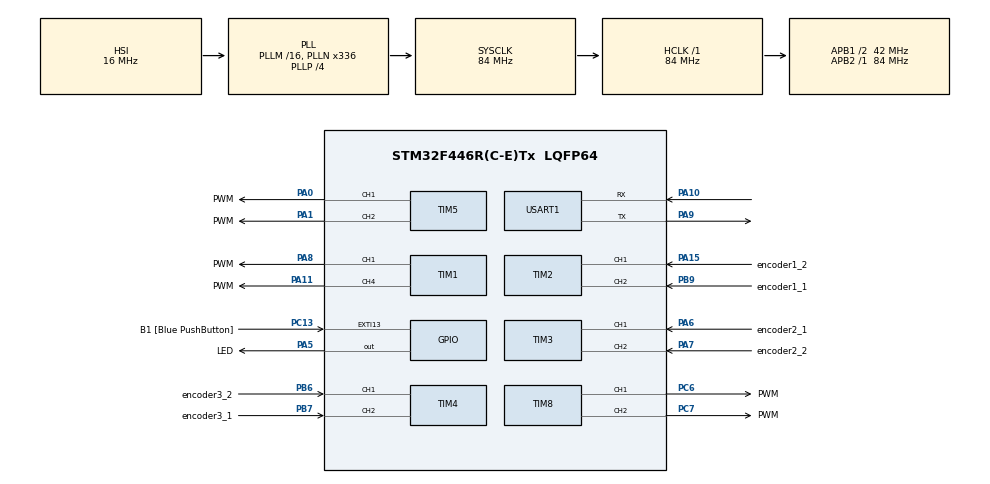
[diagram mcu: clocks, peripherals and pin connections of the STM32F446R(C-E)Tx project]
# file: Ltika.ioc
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Mcu.Family=STM32F4
Mcu.Name=STM32F446R(C-E)Tx
Mcu.Package=LQFP64
NVIC.PriorityGroup=NVIC_PRIORITYGROUP_0
PA0-WKUP.GPIO_Label=PWM
PA0-WKUP.Signal=S_TIM5_CH1
PA1.GPIO_Label=PWM
PA1.Signal=S_TIM5_CH2
PA10.Mode=Asynchronous
PA10.Signal=USART1_RX
PA11.GPIO_Label=PWM
PA11.Signal=S_TIM1_CH4
PA13.GPIO_Label=TMS
PA13.Signal=SYS_JTMS-SWDIO
PA14.GPIO_Label=TCK
PA14.Signal=SYS_JTCK-SWCLK
PA15.GPIO_Label=encoder1_2
PA15.Signal=S_TIM2_CH1_ETR
PA2.GPIO_Label=USART_TX
PA2.Signal=USART2_TX
PA3.GPIO_Label=USART_RX
PA3.Signal=USART2_RX
PA5.GPIO_Label=LED
PA5.Signal=GPIO_Output
PA6.GPIO_Label=encoder2_1
PA6.Signal=S_TIM3_CH1
PA7.GPIO_Label=encoder2_2
PA7.Signal=S_TIM3_CH2
PA8.GPIO_Label=PWM
PA8.Signal=S_TIM1_CH1
PA9.Mode=Asynchronous
PA9.Signal=USART1_TX
PB3.GPIO_Label=SWO
PB3.Signal=SYS_JTDO-SWO
PB6.GPIO_Label=encoder3_2
PB6.Signal=S_TIM4_CH1
PB7.GPIO_Label=encoder3_1
PB7.Signal=S_TIM4_CH2
PB9.GPIO_Label=encoder1_1
PB9.Signal=S_TIM2_CH2
PC13.GPIO_Label=B1 [Blue PushButton]
PC13.GPIO_ModeDefaultEXTI=GPIO_MODE_IT_FALLING
PC13.Signal=GPXTI13
PC14-OSC32_IN.Signal=RCC_OSC32_IN
PC15-OSC32_OUT.Signal=RCC_OSC32_OUT
PC6.GPIO_Label=PWM
PC6.Signal=S_TIM8_CH1
PC7.GPIO_Label=PWM
PC7.Signal=S_TIM8_CH2
PH0-OSC_IN.Signal=RCC_OSC_IN
PH1-OSC_OUT.Signal=RCC_OSC_OUT
ProjectManager.HeapSize=0x200
ProjectManager.StackSize=0x400
ProjectManager.TargetToolchain=STM32CubeIDE
RCC.AHBFreq_Value=84000000
RCC.APB1CLKDivider=RCC_HCLK_DIV2
RCC.APB1Freq_Value=42000000
RCC.APB1TimFreq_Value=84000000
RCC.APB2Freq_Value=84000000
RCC.APB2TimFreq_Value=84000000
RCC.CortexFreq_Value=84000000
RCC.FLatency-AdvancedSettings=FLASH_LATENCY_2
RCC.HCLKFreq_Value=84000000
RCC.HSE_VALUE=8000000
RCC.HSI_VALUE=16000000
RCC.LSE_VALUE=32768
RCC.PLLN=336
RCC.PLLP=RCC_PLLP_DIV4
RCC.SYSCLKFreq_VALUE=84000000
RCC.SYSCLKSource=RCC_SYSCLKSOURCE_PLLCLK
RCC.USBFreq_Value=168000000
RCC.VCOOutputFreq_Value=336000000
SH.S_TIM1_CH1.0=TIM1_CH1,PWM Generation1 CH1
SH.S_TIM1_CH4.0=TIM1_CH4,PWM Generation4 CH4
SH.S_TIM2_CH1_ETR.0=TIM2_CH1,Encoder_Interface
SH.S_TIM2_CH2.0=TIM2_CH2,Encoder_Interface
SH.S_TIM3_CH1.0=TIM3_CH1,Encoder_Interface
SH.S_TIM3_CH2.0=TIM3_CH2,Encoder_Interface
SH.S_TIM4_CH1.0=TIM4_CH1,Encoder_Interface
SH.S_TIM4_CH2.0=TIM4_CH2,Encoder_Interface
SH.S_TIM5_CH1.0=TIM5_CH1,PWM Generation1 CH1
SH.S_TIM5_CH2.0=TIM5_CH2,PWM Generation2 CH2
SH.S_TIM8_CH1.0=TIM8_CH1,PWM Generation1 CH1
SH.S_TIM8_CH2.0=TIM8_CH2,PWM Generation2 CH2
TIM1.Channel-PWM\ Generation1\ CH1=TIM_CHANNEL_1
TIM1.Channel-PWM\ Generation4\ CH4=TIM_CHANNEL_4
TIM5.Channel-PWM\ Generation1\ CH1=TIM_CHANNEL_1
TIM5.Channel-PWM\ Generation2\ CH2=TIM_CHANNEL_2
TIM8.Channel-PWM\ Generation1\ CH1=TIM_CHANNEL_1
TIM8.Channel-PWM\ Generation2\ CH2=TIM_CHANNEL_2
USART1.VirtualMode=VM_ASYNC
board=NUCLEO-F446RE

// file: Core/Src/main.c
/* USER CODE BEGIN Header */
/**
  ******************************************************************************
  * @file           : main.c
  * @brief          : Main program body
  ******************************************************************************
  * @attention
  *
  * Copyright (c) 2023 STMicroelectronics.
  * All rights reserved.
  *
  * This software is licensed under terms that can be found in the LICENSE file
  * in the root directory of this software component.
  * If no LICENSE file comes with this software, it is provided AS-IS.
  *
  ******************************************************************************
  */
/* USER CODE END Header */
#include "main.h"

TIM_HandleTypeDef htim1;
TIM_HandleTypeDef htim2;
TIM_HandleTypeDef htim3;
TIM_HandleTypeDef htim4;
TIM_HandleTypeDef htim5;
TIM_HandleTypeDef htim8;

UART_HandleTypeDef huart1;

void SystemClock_Config(void);
static void MX_GPIO_Init(void);
static void MX_TIM2_Init(void);
static void MX_TIM3_Init(void);
static void MX_TIM4_Init(void);
static void MX_TIM5_Init(void);
static void MX_TIM8_Init(void);
static void MX_USART1_UART_Init(void);
static void MX_TIM1_Init(void);

int main(void)
{

  /* MCU Configuration--------------------------------------------------------*/

  /* Reset of all peripherals, Initializes the Flash interface and the Systick. */
  HAL_Init();

  /* Configure the system clock */
  SystemClock_Config();

  /* Initialize all configured peripherals */
  MX_GPIO_Init();
  MX_TIM2_Init();
  MX_TIM3_Init();
  MX_TIM4_Init();
  MX_TIM5_Init();
  MX_TIM8_Init();
  MX_USART1_UART_Init();
  MX_TIM1_Init();

  /* Infinite loop */
  while (1)
  {

    /* USER CODE BEGIN 3 */
	//  HAL_GPIO_WritePin(GPIOA,GPIO_PIN_5,GPIO_PIN_SET);//LED点灯
	  HAL_GPIO_WritePin(LED_GPIO_Port,LED_Pin,GPIO_PIN_SET);//LED点灯
	  HAL_Delay(500);
	//  HAL_GPIO_WritePin(GPIOA,GPIO_PIN_5,GPIO_PIN_RESET);//LED消�?�
	//  HAL_GPIO_WritePin(LED_GPIO_Port,LED_Pin,GPIO_PIN_RESET);//LED消�?�
	//  HAL_Delay(500);
  }
  /* USER CODE END 3 */
}

void SystemClock_Config(void)
{
  RCC_OscInitTypeDef RCC_OscInitStruct = {0};
  RCC_ClkInitTypeDef RCC_ClkInitStruct = {0};

  /** Configure the main internal regulator output voltage
  */
  __HAL_RCC_PWR_CLK_ENABLE();
  __HAL_PWR_VOLTAGESCALING_CONFIG(PWR_REGULATOR_VOLTAGE_SCALE3);

  /** Initializes the RCC Oscillators according to the specified parameters
  * in the RCC_OscInitTypeDef structure.
  */
  RCC_OscInitStruct.OscillatorType = RCC_OSCILLATORTYPE_HSI;
  RCC_OscInitStruct.HSIState = RCC_HSI_ON;
  RCC_OscInitStruct.HSICalibrationValue = RCC_HSICALIBRATION_DEFAULT;
  RCC_OscInitStruct.PLL.PLLState = RCC_PLL_ON;
  RCC_OscInitStruct.PLL.PLLSource = RCC_PLLSOURCE_HSI;
  RCC_OscInitStruct.PLL.PLLM = 16;
  RCC_OscInitStruct.PLL.PLLN = 336;
  RCC_OscInitStruct.PLL.PLLP = RCC_PLLP_DIV4;
  RCC_OscInitStruct.PLL.PLLQ = 2;
  RCC_OscInitStruct.PLL.PLLR = 2;
  if (HAL_RCC_OscConfig(&RCC_OscInitStruct) != HAL_OK)
  {
    Error_Handler();
  }

  /** Initializes the CPU, AHB and APB buses clocks
  */
  RCC_ClkInitStruct.ClockType = RCC_CLOCKTYPE_HCLK|RCC_CLOCKTYPE_SYSCLK
                              |RCC_CLOCKTYPE_PCLK1|RCC_CLOCKTYPE_PCLK2;
  RCC_ClkInitStruct.SYSCLKSource = RCC_SYSCLKSOURCE_PLLCLK;
  RCC_ClkInitStruct.AHBCLKDivider = RCC_SYSCLK_DIV1;
  RCC_ClkInitStruct.APB1CLKDivider = RCC_HCLK_DIV2;
  RCC_ClkInitStruct.APB2CLKDivider = RCC_HCLK_DIV1;

  if (HAL_RCC_ClockConfig(&RCC_ClkInitStruct, FLASH_LATENCY_2) != HAL_OK)
  {
    Error_Handler();
  }
}

static void MX_TIM1_Init(void)
{

  TIM_MasterConfigTypeDef sMasterConfig = {0};
  TIM_OC_InitTypeDef sConfigOC = {0};
  TIM_BreakDeadTimeConfigTypeDef sBreakDeadTimeConfig = {0};

  htim1.Instance = TIM1;
  htim1.Init.Prescaler = 0;
  htim1.Init.CounterMode = TIM_COUNTERMODE_UP;
  htim1.Init.Period = 65535;
  htim1.Init.ClockDivision = TIM_CLOCKDIVISION_DIV1;
  htim1.Init.RepetitionCounter = 0;
  htim1.Init.AutoReloadPreload = TIM_AUTORELOAD_PRELOAD_DISABLE;
  if (HAL_TIM_PWM_Init(&htim1) != HAL_OK)
  {
    Error_Handler();
  }
  sMasterConfig.MasterOutputTrigger = TIM_TRGO_RESET;
  sMasterConfig.MasterSlaveMode = TIM_MASTERSLAVEMODE_DISABLE;
  if (HAL_TIMEx_MasterConfigSynchronization(&htim1, &sMasterConfig) != HAL_OK)
  {
    Error_Handler();
  }
  sConfigOC.OCMode = TIM_OCMODE_PWM1;
  sConfigOC.Pulse = 0;
  sConfigOC.OCPolarity = TIM_OCPOLARITY_HIGH;
  sConfigOC.OCNPolarity = TIM_OCNPOLARITY_HIGH;
  sConfigOC.OCFastMode = TIM_OCFAST_DISABLE;
  sConfigOC.OCIdleState = TIM_OCIDLESTATE_RESET;
  sConfigOC.OCNIdleState = TIM_OCNIDLESTATE_RESET;
  if (HAL_TIM_PWM_ConfigChannel(&htim1, &sConfigOC, TIM_CHANNEL_1) != HAL_OK)
  {
    Error_Handler();
  }
  if (HAL_TIM_PWM_ConfigChannel(&htim1, &sConfigOC, TIM_CHANNEL_4) != HAL_OK)
  {
    Error_Handler();
  }
  sBreakDeadTimeConfig.OffStateRunMode = TIM_OSSR_DISABLE;
  sBreakDeadTimeConfig.OffStateIDLEMode = TIM_OSSI_DISABLE;
  sBreakDeadTimeConfig.LockLevel = TIM_LOCKLEVEL_OFF;
  sBreakDeadTimeConfig.DeadTime = 0;
  sBreakDeadTimeConfig.BreakState = TIM_BREAK_DISABLE;
  sBreakDeadTimeConfig.BreakPolarity = TIM_BREAKPOLARITY_HIGH;
  sBreakDeadTimeConfig.AutomaticOutput = TIM_AUTOMATICOUTPUT_DISABLE;
  if (HAL_TIMEx_ConfigBreakDeadTime(&htim1, &sBreakDeadTimeConfig) != HAL_OK)
  {
    Error_Handler();
  }
  HAL_TIM_MspPostInit(&htim1);

}

static void MX_TIM2_Init(void)
{

  TIM_Encoder_InitTypeDef sConfig = {0};
  TIM_MasterConfigTypeDef sMasterConfig = {0};

  htim2.Instance = TIM2;
  htim2.Init.Prescaler = 0;
  htim2.Init.CounterMode = TIM_COUNTERMODE_UP;
  htim2.Init.Period = 4294967295;
  htim2.Init.ClockDivision = TIM_CLOCKDIVISION_DIV1;
  htim2.Init.AutoReloadPreload = TIM_AUTORELOAD_PRELOAD_DISABLE;
  sConfig.EncoderMode = TIM_ENCODERMODE_TI1;
  sConfig.IC1Polarity = TIM_ICPOLARITY_RISING;
  sConfig.IC1Selection = TIM_ICSELECTION_DIRECTTI;
  sConfig.IC1Prescaler = TIM_ICPSC_DIV1;
  sConfig.IC1Filter = 0;
  sConfig.IC2Polarity = TIM_ICPOLARITY_RISING;
  sConfig.IC2Selection = TIM_ICSELECTION_DIRECTTI;
  sConfig.IC2Prescaler = TIM_ICPSC_DIV1;
  sConfig.IC2Filter = 0;
  if (HAL_TIM_Encoder_Init(&htim2, &sConfig) != HAL_OK)
  {
    Error_Handler();
  }
  sMasterConfig.MasterOutputTrigger = TIM_TRGO_RESET;
  sMasterConfig.MasterSlaveMode = TIM_MASTERSLAVEMODE_DISABLE;
  if (HAL_TIMEx_MasterConfigSynchronization(&htim2, &sMasterConfig) != HAL_OK)
  {
    Error_Handler();
  }

}

static void MX_TIM3_Init(void)
{

  TIM_Encoder_InitTypeDef sConfig = {0};
  TIM_MasterConfigTypeDef sMasterConfig = {0};

  htim3.Instance = TIM3;
  htim3.Init.Prescaler = 0;
  htim3.Init.CounterMode = TIM_COUNTERMODE_UP;
  htim3.Init.Period = 65535;
  htim3.Init.ClockDivision = TIM_CLOCKDIVISION_DIV1;
  htim3.Init.AutoReloadPreload = TIM_AUTORELOAD_PRELOAD_DISABLE;
  sConfig.EncoderMode = TIM_ENCODERMODE_TI1;
  sConfig.IC1Polarity = TIM_ICPOLARITY_RISING;
  sConfig.IC1Selection = TIM_ICSELECTION_DIRECTTI;
  sConfig.IC1Prescaler = TIM_ICPSC_DIV1;
  sConfig.IC1Filter = 0;
  sConfig.IC2Polarity = TIM_ICPOLARITY_RISING;
  sConfig.IC2Selection = TIM_ICSELECTION_DIRECTTI;
  sConfig.IC2Prescaler = TIM_ICPSC_DIV1;
  sConfig.IC2Filter = 0;
  if (HAL_TIM_Encoder_Init(&htim3, &sConfig) != HAL_OK)
  {
    Error_Handler();
  }
  sMasterConfig.MasterOutputTrigger = TIM_TRGO_RESET;
  sMasterConfig.MasterSlaveMode = TIM_MASTERSLAVEMODE_DISABLE;
  if (HAL_TIMEx_MasterConfigSynchronization(&htim3, &sMasterConfig) != HAL_OK)
  {
    Error_Handler();
  }

}

static void MX_TIM4_Init(void)
{

  TIM_Encoder_InitTypeDef sConfig = {0};
  TIM_MasterConfigTypeDef sMasterConfig = {0};

  htim4.Instance = TIM4;
  htim4.Init.Prescaler = 0;
  htim4.Init.CounterMode = TIM_COUNTERMODE_UP;
  htim4.Init.Period = 65535;
  htim4.Init.ClockDivision = TIM_CLOCKDIVISION_DIV1;
  htim4.Init.AutoReloadPreload = TIM_AUTORELOAD_PRELOAD_DISABLE;
  sConfig.EncoderMode = TIM_ENCODERMODE_TI1;
  sConfig.IC1Polarity = TIM_ICPOLARITY_RISING;
  sConfig.IC1Selection = TIM_ICSELECTION_DIRECTTI;
  sConfig.IC1Prescaler = TIM_ICPSC_DIV1;
  sConfig.IC1Filter = 0;
  sConfig.IC2Polarity = TIM_ICPOLARITY_RISING;
  sConfig.IC2Selection = TIM_ICSELECTION_DIRECTTI;
  sConfig.IC2Prescaler = TIM_ICPSC_DIV1;
  sConfig.IC2Filter = 0;
  if (HAL_TIM_Encoder_Init(&htim4, &sConfig) != HAL_OK)
  {
    Error_Handler();
  }
  sMasterConfig.MasterOutputTrigger = TIM_TRGO_RESET;
  sMasterConfig.MasterSlaveMode = TIM_MASTERSLAVEMODE_DISABLE;
  if (HAL_TIMEx_MasterConfigSynchronization(&htim4, &sMasterConfig) != HAL_OK)
  {
    Error_Handler();
  }

}

static void MX_TIM5_Init(void)
{

  TIM_MasterConfigTypeDef sMasterConfig = {0};
  TIM_OC_InitTypeDef sConfigOC = {0};

  htim5.Instance = TIM5;
  htim5.Init.Prescaler = 0;
  htim5.Init.CounterMode = TIM_COUNTERMODE_UP;
  htim5.Init.Period = 4294967295;
  htim5.Init.ClockDivision = TIM_CLOCKDIVISION_DIV1;
  htim5.Init.AutoReloadPreload = TIM_AUTORELOAD_PRELOAD_DISABLE;
  if (HAL_TIM_PWM_Init(&htim5) != HAL_OK)
  {
    Error_Handler();
  }
  sMasterConfig.MasterOutputTrigger = TIM_TRGO_RESET;
  sMasterConfig.MasterSlaveMode = TIM_MASTERSLAVEMODE_DISABLE;
  if (HAL_TIMEx_MasterConfigSynchronization(&htim5, &sMasterConfig) != HAL_OK)
  {
    Error_Handler();
  }
  sConfigOC.OCMode = TIM_OCMODE_PWM1;
  sConfigOC.Pulse = 0;
  sConfigOC.OCPolarity = TIM_OCPOLARITY_HIGH;
  sConfigOC.OCFastMode = TIM_OCFAST_DISABLE;
  if (HAL_TIM_PWM_ConfigChannel(&htim5, &sConfigOC, TIM_CHANNEL_1) != HAL_OK)
  {
    Error_Handler();
  }
  if (HAL_TIM_PWM_ConfigChannel(&htim5, &sConfigOC, TIM_CHANNEL_2) != HAL_OK)
  {
    Error_Handler();
  }
  HAL_TIM_MspPostInit(&htim5);

}

static void MX_TIM8_Init(void)
{

  TIM_MasterConfigTypeDef sMasterConfig = {0};
  TIM_OC_InitTypeDef sConfigOC = {0};
  TIM_BreakDeadTimeConfigTypeDef sBreakDeadTimeConfig = {0};

  htim8.Instance = TIM8;
  htim8.Init.Prescaler = 0;
  htim8.Init.CounterMode = TIM_COUNTERMODE_UP;
  htim8.Init.Period = 65535;
  htim8.Init.ClockDivision = TIM_CLOCKDIVISION_DIV1;
  htim8.Init.RepetitionCounter = 0;
  htim8.Init.AutoReloadPreload = TIM_AUTORELOAD_PRELOAD_DISABLE;
  if (HAL_TIM_PWM_Init(&htim8) != HAL_OK)
  {
    Error_Handler();
  }
  sMasterConfig.MasterOutputTrigger = TIM_TRGO_RESET;
  sMasterConfig.MasterSlaveMode = TIM_MASTERSLAVEMODE_DISABLE;
  if (HAL_TIMEx_MasterConfigSynchronization(&htim8, &sMasterConfig) != HAL_OK)
  {
    Error_Handler();
  }
  sConfigOC.OCMode = TIM_OCMODE_PWM1;
  sConfigOC.Pulse = 0;
  sConfigOC.OCPolarity = TIM_OCPOLARITY_HIGH;
  sConfigOC.OCNPolarity = TIM_OCNPOLARITY_HIGH;
  sConfigOC.OCFastMode = TIM_OCFAST_DISABLE;
  sConfigOC.OCIdleState = TIM_OCIDLESTATE_RESET;
  sConfigOC.OCNIdleState = TIM_OCNIDLESTATE_RESET;
  if (HAL_TIM_PWM_ConfigChannel(&htim8, &sConfigOC, TIM_CHANNEL_1) != HAL_OK)
  {
    Error_Handler();
  }
  if (HAL_TIM_PWM_ConfigChannel(&htim8, &sConfigOC, TIM_CHANNEL_2) != HAL_OK)
  {
    Error_Handler();
  }
  sBreakDeadTimeConfig.OffStateRunMode = TIM_OSSR_DISABLE;
  sBreakDeadTimeConfig.OffStateIDLEMode = TIM_OSSI_DISABLE;
  sBreakDeadTimeConfig.LockLevel = TIM_LOCKLEVEL_OFF;
  sBreakDeadTimeConfig.DeadTime = 0;
  sBreakDeadTimeConfig.BreakState = TIM_BREAK_DISABLE;
  sBreakDeadTimeConfig.BreakPolarity = TIM_BREAKPOLARITY_HIGH;
  sBreakDeadTimeConfig.AutomaticOutput = TIM_AUTOMATICOUTPUT_DISABLE;
  if (HAL_TIMEx_ConfigBreakDeadTime(&htim8, &sBreakDeadTimeConfig) != HAL_OK)
  {
    Error_Handler();
  }
  HAL_TIM_MspPostInit(&htim8);

}

static void MX_USART1_UART_Init(void)
{

  huart1.Instance = USART1;
  huart1.Init.BaudRate = 115200;
  huart1.Init.WordLength = UART_WORDLENGTH_8B;
  huart1.Init.StopBits = UART_STOPBITS_1;
  huart1.Init.Parity = UART_PARITY_NONE;
  huart1.Init.Mode = UART_MODE_TX_RX;
  huart1.Init.HwFlowCtl = UART_HWCONTROL_NONE;
  huart1.Init.OverSampling = UART_OVERSAMPLING_16;
  if (HAL_UART_Init(&huart1) != HAL_OK)
  {
    Error_Handler();
  }

}

static void MX_GPIO_Init(void)
{
  GPIO_InitTypeDef GPIO_InitStruct = {0};

  /* GPIO Ports Clock Enable */
  __HAL_RCC_GPIOC_CLK_ENABLE();
  __HAL_RCC_GPIOH_CLK_ENABLE();
  __HAL_RCC_GPIOA_CLK_ENABLE();
  __HAL_RCC_GPIOB_CLK_ENABLE();

  /*Configure GPIO pin Output Level */
  HAL_GPIO_WritePin(LED_GPIO_Port, LED_Pin, GPIO_PIN_RESET);

  /*Configure GPIO pin : B1_Pin */
  GPIO_InitStruct.Pin = B1_Pin;
  GPIO_InitStruct.Mode = GPIO_MODE_IT_FALLING;
  GPIO_InitStruct.Pull = GPIO_NOPULL;
  HAL_GPIO_Init(B1_GPIO_Port, &GPIO_InitStruct);

  /*Configure GPIO pins : USART_TX_Pin USART_RX_Pin */
  GPIO_InitStruct.Pin = USART_TX_Pin|USART_RX_Pin;
  GPIO_InitStruct.Mode = GPIO_MODE_AF_PP;
  GPIO_InitStruct.Pull = GPIO_NOPULL;
  GPIO_InitStruct.Speed = GPIO_SPEED_FREQ_VERY_HIGH;
  GPIO_InitStruct.Alternate = GPIO_AF7_USART2;
  HAL_GPIO_Init(GPIOA, &GPIO_InitStruct);

  /*Configure GPIO pin : LED_Pin */
  GPIO_InitStruct.Pin = LED_Pin;
  GPIO_InitStruct.Mode = GPIO_MODE_OUTPUT_PP;
  GPIO_InitStruct.Pull = GPIO_NOPULL;
  GPIO_InitStruct.Speed = GPIO_SPEED_FREQ_LOW;
  HAL_GPIO_Init(LED_GPIO_Port, &GPIO_InitStruct);

}

void Error_Handler(void)
{
  __disable_irq();
  while (1)
  {
  }
}
